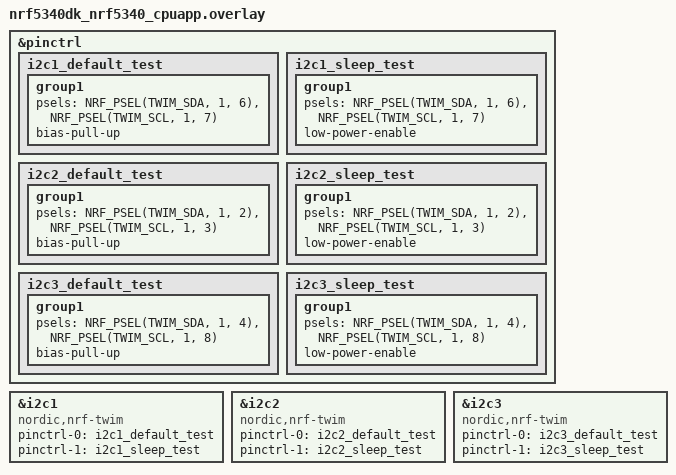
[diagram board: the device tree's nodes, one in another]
/*
 * Copyright (c) 2026 Nordic Semiconductor ASA
 *
 * SPDX-License-Identifier: LicenseRef-Nordic-5-Clause
 */

&pinctrl {
	i2c1_default_test: i2c1_default_test {
		group1 {
			psels = <NRF_PSEL(TWIM_SDA, 1, 6)>,
				<NRF_PSEL(TWIM_SCL, 1, 7)>;
			bias-pull-up;
		};
	};

	i2c1_sleep_test: i2c1_sleep_test {
		group1 {
			psels = <NRF_PSEL(TWIM_SDA, 1, 6)>,
				<NRF_PSEL(TWIM_SCL, 1, 7)>;
			low-power-enable;
		};
	};

	i2c2_default_test: i2c2_default_test {
		group1 {
			psels = <NRF_PSEL(TWIM_SDA, 1, 2)>,
				<NRF_PSEL(TWIM_SCL, 1, 3)>;
			bias-pull-up;
		};
	};

	i2c2_sleep_test: i2c2_sleep_test {
		group1 {
			psels = <NRF_PSEL(TWIM_SDA, 1, 2)>,
				<NRF_PSEL(TWIM_SCL, 1, 3)>;
			low-power-enable;
		};
	};

	i2c3_default_test: i2c3_default_test {
		group1 {
			psels = <NRF_PSEL(TWIM_SDA, 1, 4)>,
				<NRF_PSEL(TWIM_SCL, 1, 8)>;
			bias-pull-up;
		};
	};

	i2c3_sleep_test: i2c3_sleep_test {
		group1 {
			psels = <NRF_PSEL(TWIM_SDA, 1, 4)>,
				<NRF_PSEL(TWIM_SCL, 1, 8)>;
			low-power-enable;
		};
	};
};

&i2c1 {
	compatible = "nordic,nrf-twim";
	status = "okay";
	pinctrl-0 = <&i2c1_default_test>;
	pinctrl-1 = <&i2c1_sleep_test>;
	pinctrl-names = "default", "sleep";
};

&i2c2 {
	compatible = "nordic,nrf-twim";
	status = "okay";
	pinctrl-0 = <&i2c2_default_test>;
	pinctrl-1 = <&i2c2_sleep_test>;
	pinctrl-names = "default", "sleep";
};

&i2c3 {
	compatible = "nordic,nrf-twim";
	status = "okay";
	pinctrl-0 = <&i2c3_default_test>;
	pinctrl-1 = <&i2c3_sleep_test>;
	pinctrl-names = "default", "sleep";
};
